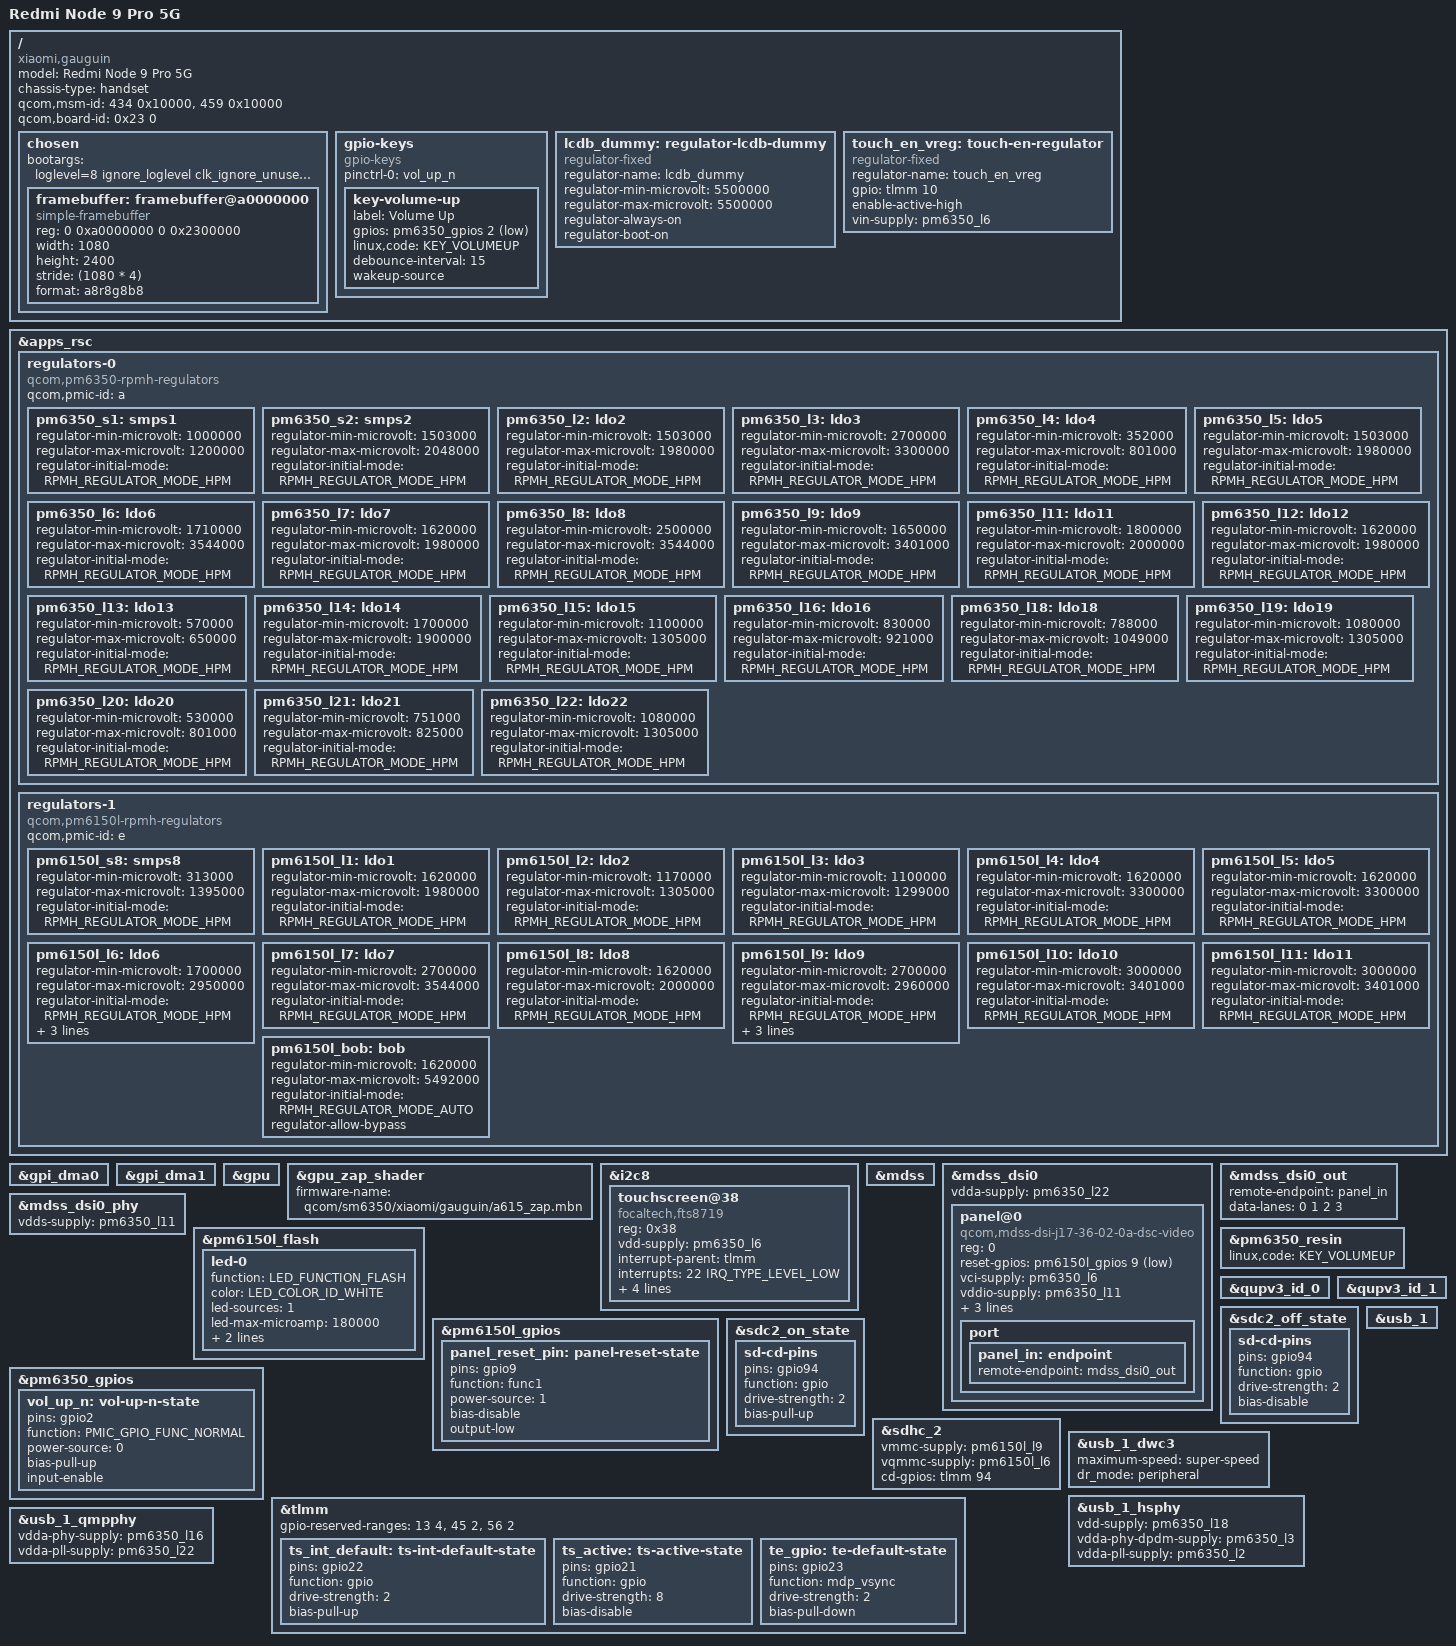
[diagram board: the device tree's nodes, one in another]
// SPDX-License-Identifier: BSD-3-Clause
/*
 * Copyright (c) 2021, Konrad Dybcio <konrad.dybcio@somainline.org>
 */
/dts-v1/;

#include <dt-bindings/leds/common.h>
#include <dt-bindings/pinctrl/qcom,pmic-gpio.h>
#include <dt-bindings/regulator/qcom,rpmh-regulator.h>
#include "sm7225.dtsi"
#include "pm6150l.dtsi"
#include "pm6350.dtsi"

/ {
	model = "Redmi Node 9 Pro 5G";
	compatible = "xiaomi,gauguin", "qcom,sm6350";
	chassis-type = "handset";
	qcom,msm-id = <434 0x10000>, <459 0x10000>;
	qcom,board-id = <0x23 0>;

	chosen {
		#address-cells = <2>;
		#size-cells = <2>;
		ranges;
		// bootargs = "loglevel=8 ignore_loglevel clk_ignore_unused pd_ignore_unused nowatchdog nomodeset modprobe.blacklist=msm,msm_drm initcall_blacklist=msm_drm_register drm.debug=0x0 video=simplefb:off console=tty0";
                bootargs = "loglevel=8 ignore_loglevel clk_ignore_unused pd_ignore_unused nowatchdog console=tty0 earlycon=keep panic=180 drm.debug=0x4";
		framebuffer: framebuffer@a0000000 {
			compatible = "simple-framebuffer";
			reg = <0 0xa0000000 0 0x2300000>;
			width = <1080>;
			height = <2400>;
			stride = <(1080 * 4)>;
			format = "a8r8g8b8";
		};
	};


    gpio-keys {
        compatible = "gpio-keys";
        pinctrl-names = "default";
        pinctrl-0 = <&vol_up_n>; 

        key-volume-up {
            label = "Volume Up";
            gpios = <&pm6350_gpios 2 GPIO_ACTIVE_LOW>;
            linux,code = <KEY_VOLUMEUP>;
            debounce-interval = <15>;
            wakeup-source;        
        };
    };

	lcdb_dummy: regulator-lcdb-dummy {
		compatible = "regulator-fixed";
		regulator-name = "lcdb_dummy";
		regulator-min-microvolt = <5500000>;
		regulator-max-microvolt = <5500000>;
		regulator-always-on;
		regulator-boot-on;
	};

	touch_en_vreg: touch-en-regulator {
		compatible = "regulator-fixed";
		regulator-name = "touch_en_vreg";
		gpio = <&tlmm 10 GPIO_ACTIVE_HIGH>;
		enable-active-high;

		vin-supply = <&pm6350_l6>;
	};
};

&apps_rsc {
	regulators-0 {
		compatible = "qcom,pm6350-rpmh-regulators";
		qcom,pmic-id = "a";

		pm6350_s1: smps1 {
			regulator-min-microvolt = <1000000>;
			regulator-max-microvolt = <1200000>;
			regulator-initial-mode = <RPMH_REGULATOR_MODE_HPM>;
		};

		pm6350_s2: smps2 {
			regulator-min-microvolt = <1503000>;
			regulator-max-microvolt = <2048000>;
			regulator-initial-mode = <RPMH_REGULATOR_MODE_HPM>;
		};

		pm6350_l2: ldo2 {
			regulator-min-microvolt = <1503000>;
			regulator-max-microvolt = <1980000>;
			regulator-initial-mode = <RPMH_REGULATOR_MODE_HPM>;
		};

		pm6350_l3: ldo3 {
			regulator-min-microvolt = <2700000>;
			regulator-max-microvolt = <3300000>;
			regulator-initial-mode = <RPMH_REGULATOR_MODE_HPM>;
		};

		pm6350_l4: ldo4 {
			regulator-min-microvolt = <352000>;
			regulator-max-microvolt = <801000>;
			regulator-initial-mode = <RPMH_REGULATOR_MODE_HPM>;
		};

		pm6350_l5: ldo5 {
			regulator-min-microvolt = <1503000>;
			regulator-max-microvolt = <1980000>;
			regulator-initial-mode = <RPMH_REGULATOR_MODE_HPM>;
		};

		pm6350_l6: ldo6 {
			regulator-min-microvolt = <1710000>;
			regulator-max-microvolt = <3544000>;
			regulator-initial-mode = <RPMH_REGULATOR_MODE_HPM>;
		};

		pm6350_l7: ldo7 {
			regulator-min-microvolt = <1620000>;
			regulator-max-microvolt = <1980000>;
			regulator-initial-mode = <RPMH_REGULATOR_MODE_HPM>;
		};

		pm6350_l8: ldo8 {
			regulator-min-microvolt = <2500000>;
			regulator-max-microvolt = <3544000>;
			regulator-initial-mode = <RPMH_REGULATOR_MODE_HPM>;
		};

		pm6350_l9: ldo9 {
			regulator-min-microvolt = <1650000>;
			regulator-max-microvolt = <3401000>;
			regulator-initial-mode = <RPMH_REGULATOR_MODE_HPM>;
		};

		pm6350_l11: ldo11 {
			regulator-min-microvolt = <1800000>;
			regulator-max-microvolt = <2000000>;
			regulator-initial-mode = <RPMH_REGULATOR_MODE_HPM>;
		};

		pm6350_l12: ldo12 {
			regulator-min-microvolt = <1620000>;
			regulator-max-microvolt = <1980000>;
			regulator-initial-mode = <RPMH_REGULATOR_MODE_HPM>;
		};

		pm6350_l13: ldo13 {
			regulator-min-microvolt = <570000>;
			regulator-max-microvolt = <650000>;
			regulator-initial-mode = <RPMH_REGULATOR_MODE_HPM>;
		};

		pm6350_l14: ldo14 {
			regulator-min-microvolt = <1700000>;
			regulator-max-microvolt = <1900000>;
			regulator-initial-mode = <RPMH_REGULATOR_MODE_HPM>;
		};

		pm6350_l15: ldo15 {
			regulator-min-microvolt = <1100000>;
			regulator-max-microvolt = <1305000>;
			regulator-initial-mode = <RPMH_REGULATOR_MODE_HPM>;
		};

		pm6350_l16: ldo16 {
			regulator-min-microvolt = <830000>;
			regulator-max-microvolt = <921000>;
			regulator-initial-mode = <RPMH_REGULATOR_MODE_HPM>;
		};

		pm6350_l18: ldo18 {
			regulator-min-microvolt = <788000>;
			regulator-max-microvolt = <1049000>;
			regulator-initial-mode = <RPMH_REGULATOR_MODE_HPM>;
		};

		pm6350_l19: ldo19 {
			regulator-min-microvolt = <1080000>;
			regulator-max-microvolt = <1305000>;
			regulator-initial-mode = <RPMH_REGULATOR_MODE_HPM>;
		};

		pm6350_l20: ldo20 {
			regulator-min-microvolt = <530000>;
			regulator-max-microvolt = <801000>;
			regulator-initial-mode = <RPMH_REGULATOR_MODE_HPM>;
		};

		pm6350_l21: ldo21 {
			regulator-min-microvolt = <751000>;
			regulator-max-microvolt = <825000>;
			regulator-initial-mode = <RPMH_REGULATOR_MODE_HPM>;
		};

		pm6350_l22: ldo22 {
			regulator-min-microvolt = <1080000>;
			regulator-max-microvolt = <1305000>;
			regulator-initial-mode = <RPMH_REGULATOR_MODE_HPM>;
		};
	};

	regulators-1 {
		compatible = "qcom,pm6150l-rpmh-regulators";
		qcom,pmic-id = "e";

		pm6150l_s8: smps8 {
			regulator-min-microvolt = <313000>;
			regulator-max-microvolt = <1395000>;
			regulator-initial-mode = <RPMH_REGULATOR_MODE_HPM>;
		};

		pm6150l_l1: ldo1 {
			regulator-min-microvolt = <1620000>;
			regulator-max-microvolt = <1980000>;
			regulator-initial-mode = <RPMH_REGULATOR_MODE_HPM>;
		};

		pm6150l_l2: ldo2 {
			regulator-min-microvolt = <1170000>;
			regulator-max-microvolt = <1305000>;
			regulator-initial-mode = <RPMH_REGULATOR_MODE_HPM>;
		};

		pm6150l_l3: ldo3 {
			regulator-min-microvolt = <1100000>;
			regulator-max-microvolt = <1299000>;
			regulator-initial-mode = <RPMH_REGULATOR_MODE_HPM>;
		};

		pm6150l_l4: ldo4 {
			regulator-min-microvolt = <1620000>;
			regulator-max-microvolt = <3300000>;
			regulator-initial-mode = <RPMH_REGULATOR_MODE_HPM>;
		};

		pm6150l_l5: ldo5 {
			regulator-min-microvolt = <1620000>;
			regulator-max-microvolt = <3300000>;
			regulator-initial-mode = <RPMH_REGULATOR_MODE_HPM>;
		};

		pm6150l_l6: ldo6 {
			regulator-min-microvolt = <1700000>;
			regulator-max-microvolt = <2950000>;
			regulator-initial-mode = <RPMH_REGULATOR_MODE_HPM>;
			regulator-allow-set-load;
			regulator-allowed-modes = <RPMH_REGULATOR_MODE_LPM
						   RPMH_REGULATOR_MODE_HPM>;
		};

		pm6150l_l7: ldo7 {
			regulator-min-microvolt = <2700000>;
			regulator-max-microvolt = <3544000>;
			regulator-initial-mode = <RPMH_REGULATOR_MODE_HPM>;
		};

		pm6150l_l8: ldo8 {
			regulator-min-microvolt = <1620000>;
			regulator-max-microvolt = <2000000>;
			regulator-initial-mode = <RPMH_REGULATOR_MODE_HPM>;
		};

		pm6150l_l9: ldo9 {
			regulator-min-microvolt = <2700000>;
			regulator-max-microvolt = <2960000>;
			regulator-initial-mode = <RPMH_REGULATOR_MODE_HPM>;
			regulator-allow-set-load;
			regulator-allowed-modes = <RPMH_REGULATOR_MODE_LPM
						   RPMH_REGULATOR_MODE_HPM>;
		};

		pm6150l_l10: ldo10 {
			regulator-min-microvolt = <3000000>;
			regulator-max-microvolt = <3401000>;
			regulator-initial-mode = <RPMH_REGULATOR_MODE_HPM>;
		};

		pm6150l_l11: ldo11 {
			regulator-min-microvolt = <3000000>;
			regulator-max-microvolt = <3401000>;
			regulator-initial-mode = <RPMH_REGULATOR_MODE_HPM>;
		};

		pm6150l_bob: bob {
			regulator-min-microvolt = <1620000>;
			regulator-max-microvolt = <5492000>;
			regulator-initial-mode = <RPMH_REGULATOR_MODE_AUTO>;
			regulator-allow-bypass;
		};
	};
};

&gpi_dma0 {
	status = "okay";
};

&gpi_dma1 {
	status = "okay";
};

&gpu {
	status = "okay";
};

&gpu_zap_shader {
	firmware-name = "qcom/sm6350/xiaomi/gauguin/a615_zap.mbn";
};


&i2c8 {
    status = "okay";

    touchscreen@38 {
        compatible = "focaltech,fts8719";
        reg = <0x38>;

        vdd-supply = <&pm6350_l6>; 
        interrupt-parent = <&tlmm>;
        interrupts = <22 IRQ_TYPE_LEVEL_LOW>;
        reset-gpios = <&tlmm 21 GPIO_ACTIVE_LOW>;

        touchscreen-size-x = <1080>;
        touchscreen-size-y = <2400>;
        pinctrl-names = "default";
		pinctrl-0 = <&ts_int_default &ts_active>;
    };
};

&mdss {
	status = "okay";
};

&mdss_dsi0 {
	vdda-supply = <&pm6350_l22>;

	status = "okay";

	panel@0 {
		//  compatible = "xiaomi,j17-36-02-0a-video";
		compatible = "qcom,mdss-dsi-j17-36-02-0a-dsc-video";
		reg = <0>;

		reset-gpios = <&pm6150l_gpios 9 GPIO_ACTIVE_LOW>;

		vci-supply = <&pm6350_l6>;
		vddio-supply = <&pm6350_l11>;
		vsn-supply = <&lcdb_dummy>;
		vsp-supply = <&lcdb_dummy>;

		pinctrl-0 = <&te_gpio &panel_reset_pin>;
		pinctrl-names = "default";

		port {
			panel_in: endpoint {
				remote-endpoint = <&mdss_dsi0_out>;
			};
		};
	};
};

&mdss_dsi0_out {
	remote-endpoint = <&panel_in>;
	data-lanes = <0 1 2 3>;
};

&mdss_dsi0_phy {
	vdds-supply = <&pm6350_l11>;

	status = "okay";
};

&pm6150l_flash {
	status = "okay";

	led-0 {
		function = LED_FUNCTION_FLASH;
		color = <LED_COLOR_ID_WHITE>; // guess
		led-sources = <1>;
		led-max-microamp = <180000>;
		flash-max-microamp = <1000000>;
		flash-max-timeout-us = <1280000>;
	};
};

&pm6150l_gpios {
	panel_reset_pin: panel-reset-state {
		pins = "gpio9";
		function = "func1";
		power-source = <1>;
		bias-disable;
		output-low;
	};
};

&pm6350_gpios {
    vol_up_n: vol-up-n-state {
        pins = "gpio2";
        function = PMIC_GPIO_FUNC_NORMAL;
        power-source = <0>;
        bias-pull-up; 
        input-enable;
    };
};

&pm6350_resin {
	linux,code = <KEY_VOLUMEUP>;
	status = "okay";
};

&qupv3_id_0 {
	status = "okay";
};

&qupv3_id_1 {
	status = "okay";
};

&sdc2_off_state {
	sd-cd-pins {
		pins = "gpio94";
		function = "gpio";
		drive-strength = <2>;
		bias-disable;
	};
};

&sdc2_on_state {
	sd-cd-pins {
		pins = "gpio94";
		function = "gpio";
		drive-strength = <2>;
		bias-pull-up;
	};
};

&sdhc_2 {
	status = "okay";

	vmmc-supply = <&pm6150l_l9>;
	vqmmc-supply = <&pm6150l_l6>;

	cd-gpios = <&tlmm 94 GPIO_ACTIVE_HIGH>;
};

&tlmm {
	// gpio-reserved-ranges = gpio-reserved-ranges = <0 60>;
	// gpio-reserved-ranges = <11 83>;
	gpio-reserved-ranges = <13 4>, <45 2>, <56 2>;
    ts_int_default: ts-int-default-state {
        pins = "gpio22";
        function = "gpio";
        drive-strength = <2>;
        bias-pull-up;       
    };

    ts_active: ts-active-state {
        pins = "gpio21";
        function = "gpio";
        drive-strength = <8>;  
        bias-disable;        
    };

	te_gpio: te-default-state {
		pins = "gpio23";
		function = "mdp_vsync";
		drive-strength = <2>;
		bias-pull-down;
	};    
};



&usb_1 {
	status = "okay";
};

&usb_1_dwc3 {
	/delete-property/ usb-role-switch;
	maximum-speed = "super-speed";
	dr_mode = "peripheral";
};

&usb_1_hsphy {
	vdd-supply = <&pm6350_l18>;
	vdda-phy-dpdm-supply = <&pm6350_l3>;
	vdda-pll-supply = <&pm6350_l2>;

	status = "okay";
};

&usb_1_qmpphy {
	vdda-phy-supply = <&pm6350_l16>;
	vdda-pll-supply = <&pm6350_l22>;

	status = "okay";
};

